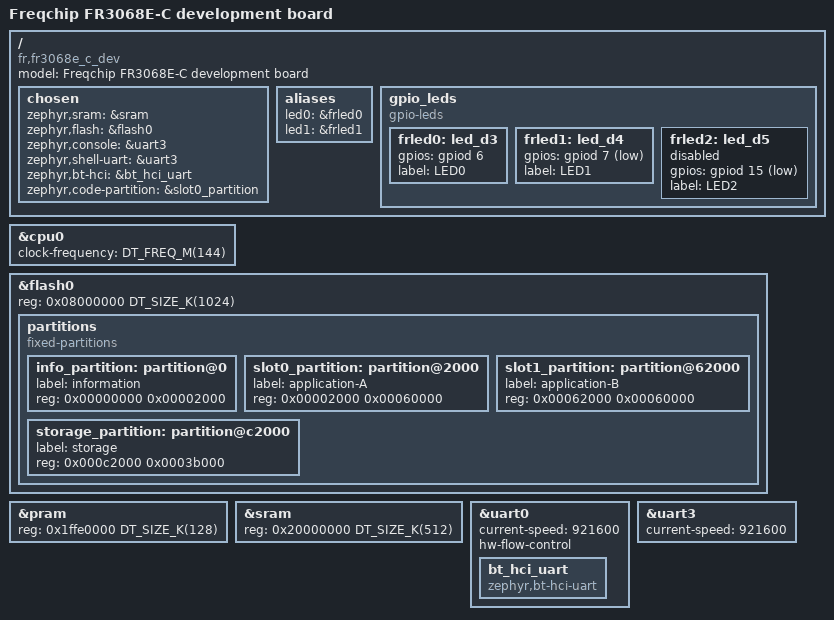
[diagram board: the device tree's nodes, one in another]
/*
 * Copyright (c) 2025 Freqchip
 * SPDX-License-Identifier: Apache-2.0
 */

/dts-v1/;

#include <freqchip/fr30xx_c/fr30xx_c.dtsi>

/ {
	model = "Freqchip FR3068E-C development board";
	compatible = "fr,fr3068e_c_dev";

	chosen {
		zephyr,sram = &sram;
		zephyr,flash = &flash0;
		zephyr,console = &uart3;
		zephyr,shell-uart = &uart3;
		zephyr,bt-hci = &bt_hci_uart;
		zephyr,code-partition = &slot0_partition; // 指向 application-A 节点
	};

	aliases {
		led0 = &frled0;
		led1 = &frled1;
	};

	/* 定义 GPIO 引脚 LED */
	gpio_leds: gpio_leds {
		compatible = "gpio-leds";
		status = "okay";

		frled0: led_d3 {
			gpios = <&gpiod 6 GPIO_ACTIVE_HIGH>;
			label = "LED0";
			status = "okay";
		};
		frled1: led_d4 {
			gpios = <&gpiod 7 GPIO_ACTIVE_LOW>;
			label = "LED1";
			status = "okay";
		};
		frled2: led_d5 {
			gpios = <&gpiod 15 GPIO_ACTIVE_LOW>;
			label = "LED2";
			status = "disabled";
		};
	};
};

&cpu0 {
	clock-frequency = <DT_FREQ_M(144)>;
};

&flash0 {
	reg = <0x08000000 DT_SIZE_K(1024)>;

	partitions {
		compatible = "fixed-partitions";
		#address-cells = <1>;
		#size-cells = <1>;

		// 示例分区定义
		info_partition: partition@0 {    // INFO分区（0x0~0x2000）
			label = "information";
			reg = <0x00000000 0x00002000>;
		};

		slot0_partition: partition@2000 { // 应用程序主分区（0x08002000~0x08062000）
			label = "application-A";
			reg = <0x00002000 0x00060000>;
		};

		slot1_partition: partition@62000 { // 应用程序备份分区（0x08062000~0x080c2000）
			label = "application-B";
			reg = <0x00062000 0x00060000>;
		};

		storage_partition: partition@c2000 { // 存储分区（0x080c2000~0x080fd000）
			label = "storage";
			reg = <0x000c2000 0x0003b000>;
		};
	};
};

&pram {
	reg = <0x1ffe0000 DT_SIZE_K(128)>;
};

&sram {
	reg = <0x20000000 DT_SIZE_K(512)>;
};

&uart0 {
	status = "okay";
	current-speed = <921600>;
	hw-flow-control;

	bt_hci_uart: bt_hci_uart {
		compatible = "zephyr,bt-hci-uart";
	};
};

&uart3 {
	status = "okay";
	current-speed = <921600>;
};

/*
&pinctrl {
	usart3_default: usart3_default {
		group1 {
			pinmux = <1, 4, 1>;
		};
		group2 {
			pinmux = <1, 5, 1>;
		};
	};

	status = "okay";
};*/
